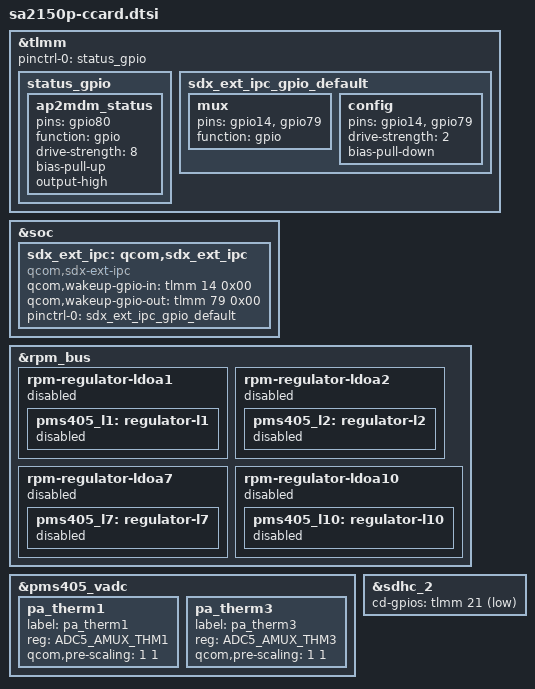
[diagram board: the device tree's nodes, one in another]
#include "qcs405.dtsi"

&tlmm {
	pinctrl-0 = <&status_gpio>;
	pinctrl-names = "default";
	status_gpio: status_gpio {
		ap2mdm_status {
			pins = "gpio80";
			function = "gpio";
			drive-strength = <8>;
			bias-pull-up;
			output-high;
		};
	};

	sdx_ext_ipc_gpio_default: sdx_ext_ipc_gpio_default {
		mux {
			pins = "gpio14", "gpio79";
			function = "gpio";
		};

		config {
			pins = "gpio14", "gpio79";
			drive-strength = <2>;
			bias-pull-down;
		};
	};
};

&soc {
	sdx_ext_ipc: qcom,sdx_ext_ipc {
		compatible = "qcom,sdx-ext-ipc";
		qcom,wakeup-gpio-in = <&tlmm 14 0x00>;
		qcom,wakeup-gpio-out = <&tlmm 79 0x00>;
		pinctrl-names = "default";
		pinctrl-0 = <&sdx_ext_ipc_gpio_default>;
	};
};

&rpm_bus {
	rpm-regulator-ldoa1 {
		status = "disabled";
		pms405_l1: regulator-l1 {
			status = "disabled";
		};
	};

	rpm-regulator-ldoa2 {
		status = "disabled";
		pms405_l2: regulator-l2 {
			status = "disabled";
		};
	};

	rpm-regulator-ldoa7 {
		status = "disabled";
		pms405_l7: regulator-l7 {
			status = "disabled";
		};
	};

	rpm-regulator-ldoa10 {
		status = "disabled";
		pms405_l10: regulator-l10 {
			status = "disabled";
		};
	};
};

&pms405_vadc {
	pa_therm1 {
		/delete-property/ qcom,ratiometric;
		 /delete-property/ qcom,hw-settle-time;
		label = "pa_therm1";
		reg = <ADC5_AMUX_THM1>;
		qcom,pre-scaling = <1 1>;
	};

	pa_therm3 {
		/delete-property/ qcom,ratiometric;
		/delete-property/ qcom,hw-settle-time;
		label = "pa_therm3";
		reg = <ADC5_AMUX_THM3>;
		qcom,pre-scaling = <1 1>;
	};
};

&sdhc_2 {
	cd-gpios = <&tlmm 21 GPIO_ACTIVE_LOW>;
};
